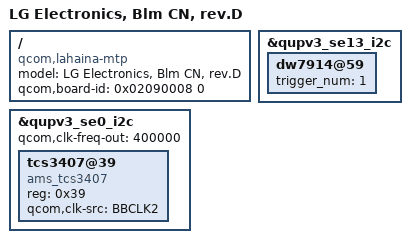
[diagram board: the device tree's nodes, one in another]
/dts-v1/;
/plugin/;

#include "lahaina-blm.dtsi"
#include "lahaina-blm-sound.dtsi"
#include "lahaina-blm-motor-rev_b.dtsi"
#include "lahaina-blm-optical-rev_e.dtsi"
#include "../lahaina-blm_camera/lahaina-blm_camera_rev-c.dtsi"
#include "../lahaina-blm_common/lahaina-blm_common-buttonless-ussys-hub_rev-1.1.dtsi"
#include "lahaina-blm-nfc-sn100.dtsi"

/ {
    model = "LG Electronics, Blm CN, rev.D";
    compatible = "qcom,lahaina-mtp", "qcom,lahaina", "qcom,mtp";
    qcom,board-id = <0x02090008 0>;
};

&qupv3_se0_i2c { /* QUP_0 (Flicker) */
	qcom,clk-freq-out = <400000>;
	status = "ok";
	tcs3407@39 {
		compatible = "ams_tcs3407";
		reg = <0x39>;
		/*
		ams,gpio_irq = <&tlmm 96 0x00>;
		interrupt-parent = <&tlmm>;
		interrupts = <96 0x0>;
		pinctrl-names = "default", "sleep";
		pinctrl-0 = <&tcs3407_int_active>;
		pinctrl-1 = <&tcs3407_int_suspend>;
		*/
		qcom,clk-src = "BBCLK2";
		status = "ok";
	};
};

&qupv3_se13_i2c {
	dw7914@59 {
		trigger_num = <1>; /*trigger pin number(how many)*/
	};
};
